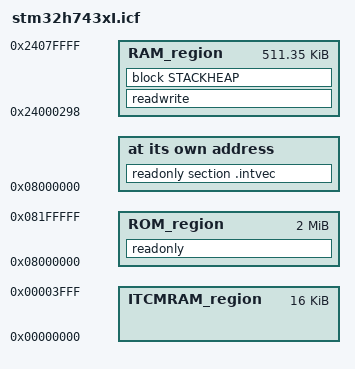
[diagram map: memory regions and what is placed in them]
/* [ROM = 2Mb = 0x200000] */
define symbol __intvec_start__     = 0x08000000;
define symbol __region_ROM_start__ = 0x08000000;
define symbol __region_ROM_end__   = 0x08000000 + 0x200000 - 1;

/* [RAM = 512kb = 0x80000] Vector table dynamic copy: 166 vectors = 664 bytes (0x298) to be reserved in RAM */
define symbol __NVIC_start__          = 0x24000000;
define symbol __NVIC_end__            = 0x24000000 + 0x298 - 1;
define symbol __region_RAM_start__    = 0x24000000 + 0x298; /* Aligned on 8 bytes */
define symbol __region_RAM_end__      = 0x24000000 + 0x80000 - 1;

define symbol __region_ITCMRAM_start__ = 0x00000000;
define symbol __region_ITCMRAM_end__   = 0x00003FFF;

/* Memory regions */
define memory mem with size = 4G;
define region ROM_region = mem:[from __region_ROM_start__ to __region_ROM_end__];
define region RAM_region = mem:[from __region_RAM_start__ to __region_RAM_end__];
define region ITCMRAM_region = mem:[from __region_ITCMRAM_start__ to __region_ITCMRAM_end__];

/* Stack and Heap */
define symbol __size_cstack__ = 0x1000;
define symbol __size_heap__   = 0x1000;
define block CSTACK    with alignment = 8, size = __size_cstack__   { };
define block HEAP      with alignment = 8, size = __size_heap__     { };
define block STACKHEAP with fixed order { block HEAP, block CSTACK };

initialize by copy with packing = zeros { readwrite };
do not initialize  { section .noinit };

place at address mem:__intvec_start__ { readonly section .intvec };

place in ROM_region   { readonly };
place in RAM_region   { readwrite, block STACKHEAP };
